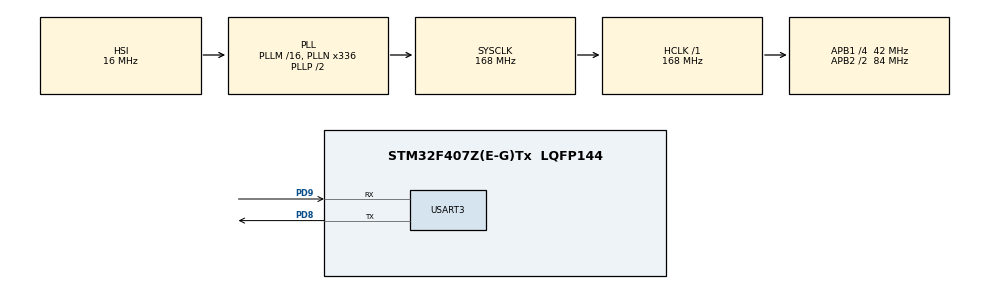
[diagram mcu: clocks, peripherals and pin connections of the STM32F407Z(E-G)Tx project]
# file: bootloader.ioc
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Dma.Request0=USART3_RX
Dma.Request1=USART3_TX
Dma.USART3_RX.0.Direction=DMA_PERIPH_TO_MEMORY
Dma.USART3_RX.0.FIFOMode=DMA_FIFOMODE_DISABLE
Dma.USART3_RX.0.Instance=DMA1_Stream1
Dma.USART3_RX.0.MemDataAlignment=DMA_MDATAALIGN_BYTE
Dma.USART3_RX.0.MemInc=DMA_MINC_ENABLE
Dma.USART3_RX.0.Mode=DMA_CIRCULAR
Dma.USART3_RX.0.PeriphDataAlignment=DMA_PDATAALIGN_BYTE
Dma.USART3_RX.0.PeriphInc=DMA_PINC_DISABLE
Dma.USART3_RX.0.Priority=DMA_PRIORITY_HIGH
Dma.USART3_TX.1.Direction=DMA_MEMORY_TO_PERIPH
Dma.USART3_TX.1.FIFOMode=DMA_FIFOMODE_DISABLE
Dma.USART3_TX.1.Instance=DMA1_Stream3
Dma.USART3_TX.1.MemDataAlignment=DMA_MDATAALIGN_BYTE
Dma.USART3_TX.1.MemInc=DMA_MINC_ENABLE
Dma.USART3_TX.1.Mode=DMA_CIRCULAR
Dma.USART3_TX.1.PeriphDataAlignment=DMA_PDATAALIGN_BYTE
Dma.USART3_TX.1.PeriphInc=DMA_PINC_DISABLE
Dma.USART3_TX.1.Priority=DMA_PRIORITY_HIGH
Mcu.Family=STM32F4
Mcu.Name=STM32F407Z(E-G)Tx
Mcu.Package=LQFP144
NVIC.DMA1_Stream1_IRQn=true\:2\:0\:true\:false\:true\:false\:true\:true
NVIC.DMA1_Stream3_IRQn=true\:2\:0\:true\:false\:true\:false\:true\:true
NVIC.PriorityGroup=NVIC_PRIORITYGROUP_4
NVIC.USART3_IRQn=true\:1\:0\:true\:false\:true\:false\:true\:true
PA13.Mode=Serial_Wire
PA13.Signal=SYS_JTMS-SWDIO
PA14.Mode=Serial_Wire
PA14.Signal=SYS_JTCK-SWCLK
PC14-OSC32_IN.Mode=LSE-External-Oscillator
PC14-OSC32_IN.Signal=RCC_OSC32_IN
PC15-OSC32_OUT.Mode=LSE-External-Oscillator
PC15-OSC32_OUT.Signal=RCC_OSC32_OUT
PD8.Mode=Asynchronous
PD8.Signal=USART3_TX
PD9.Mode=Asynchronous
PD9.Signal=USART3_RX
PH0-OSC_IN.Mode=HSE-External-Oscillator
PH0-OSC_IN.Signal=RCC_OSC_IN
PH1-OSC_OUT.Mode=HSE-External-Oscillator
PH1-OSC_OUT.Signal=RCC_OSC_OUT
ProjectManager.HeapSize=0x200
ProjectManager.StackSize=0x400
ProjectManager.TargetToolchain=MDK-ARM V5.32
RCC.48MHZClocksFreq_Value=84000000
RCC.AHBFreq_Value=168000000
RCC.APB1CLKDivider=RCC_HCLK_DIV4
RCC.APB1Freq_Value=42000000
RCC.APB1TimFreq_Value=84000000
RCC.APB2CLKDivider=RCC_HCLK_DIV2
RCC.APB2Freq_Value=84000000
RCC.APB2TimFreq_Value=168000000
RCC.CortexFreq_Value=168000000
RCC.HCLKFreq_Value=168000000
RCC.HSE_VALUE=25000000
RCC.HSI_VALUE=16000000
RCC.PLLN=336
RCC.SYSCLKFreq_VALUE=168000000
RCC.SYSCLKSource=RCC_SYSCLKSOURCE_PLLCLK
RCC.VCOOutputFreq_Value=336000000
USART3.VirtualMode=VM_ASYNC
board=custom

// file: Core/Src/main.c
/* USER CODE BEGIN Header */
/**
  ******************************************************************************
  * @file           : main.c
  * @brief          : Main program body
  ******************************************************************************
  * @attention
  *
  * Copyright (c) 2026 STMicroelectronics.
  * All rights reserved.
  *
  * This software is licensed under terms that can be found in the LICENSE file
  * in the root directory of this software component.
  * If no LICENSE file comes with this software, it is provided AS-IS.
  *
  ******************************************************************************
  */
/* USER CODE END Header */
#include "main.h"

/* USER CODE BEGIN Includes */
#include <stdio.h>
#include <stdint.h>
#include "ota_protocol.h"
#include "state_machine.h"
#include "ring_buffer.h"
#include "stm32f4xx_hal.h"
#include "task_monitor_boot.h"
/* USER CODE END Includes */

UART_HandleTypeDef huart3;
DMA_HandleTypeDef hdma_usart3_rx;
DMA_HandleTypeDef hdma_usart3_tx;

/* USER CODE BEGIN PV */
uint8_t rx_buffer[1200];
Ring_Buffer_ts uart_tp;
uint8_t parse_buffer[1200];
/* USER CODE END PV */

void SystemClock_Config(void);
static void MX_GPIO_Init(void);
static void MX_DMA_Init(void);
static void MX_USART3_UART_Init(void);
/* USER CODE BEGIN PFP */
int fputc(int ch,FILE *f)
{
  HAL_UART_Transmit(&huart3,(uint8_t*)&ch,1,10000);
  return ch;
}
/* USER CODE END PFP */

int main(void)
{

  /* MCU Configuration--------------------------------------------------------*/

  /* Reset of all peripherals, Initializes the Flash interface and the Systick. */
  HAL_Init();

  /* Configure the system clock */
  SystemClock_Config();

  /* Initialize all configured peripherals */
  MX_GPIO_Init();
  MX_DMA_Init();
  MX_USART3_UART_Init();
  /* USER CODE BEGIN 2 */
printf("\r\n====================================\r\n");
printf("Bootloader Started\r\n");
printf("\r\n====================================\r\n");

RingBuffer_Init(&uart_tp);

StateMachine_Init();

TaskMonitor_Init();

HAL_UARTEx_ReceiveToIdle_DMA(&huart3,rx_buffer,sizeof(rx_buffer));
__HAL_DMA_DISABLE_IT(&hdma_usart3_rx,DMA_IT_HT);

  /* USER CODE END 2 */

  /* Infinite loop */
  /* USER CODE BEGIN WHILE */
  while (1)
  {
    StateMachine_Run();
    TaskMonitor_Feed(TASK_ID_SM_RUN);

    for(;;)
    {
      uint32_t avail=RingBuffer_Available(&uart_tp);
      if(avail==0)
      {
        break;
      }

      uint32_t to_read=(avail>sizeof(parse_buffer))?sizeof(parse_buffer):avail;
      uint32_t read_len=RingBuffer_Read(&uart_tp,parse_buffer,to_read);

      ota_rx_flag=0;
      uint16_t used=OTA_Protocol_Parse(parse_buffer,(uint16_t)read_len);

      if(ota_rx_flag)
      {
        ota_rx_flag=0;
        StateMachine_OneFrameReceived();
      }

      if(used<read_len)
      {
        uart_tp.rd-=(read_len-used);
        if(used==0)
        {
          break;
        }
      }
    }
    TaskMonitor_Feed(TASK_ID_RINGBUF);
    TaskMonitor_Feed(TASK_ID_PROTOCOL_PARSE);
    TaskMonitor_Feed(TASK_ID_SM_RECEIVE);
    /* USER CODE END WHILE */

  }
}

void SystemClock_Config(void)
{
  RCC_OscInitTypeDef RCC_OscInitStruct = {0};
  RCC_ClkInitTypeDef RCC_ClkInitStruct = {0};

  /** Configure the main internal regulator output voltage
  */
  __HAL_RCC_PWR_CLK_ENABLE();
  __HAL_PWR_VOLTAGESCALING_CONFIG(PWR_REGULATOR_VOLTAGE_SCALE1);

  /** Initializes the RCC Oscillators according to the specified parameters
  * in the RCC_OscInitTypeDef structure.
  */
  RCC_OscInitStruct.OscillatorType = RCC_OSCILLATORTYPE_HSI;
  RCC_OscInitStruct.HSIState = RCC_HSI_ON;
  RCC_OscInitStruct.HSICalibrationValue = RCC_HSICALIBRATION_DEFAULT;
  RCC_OscInitStruct.PLL.PLLState = RCC_PLL_ON;
  RCC_OscInitStruct.PLL.PLLSource = RCC_PLLSOURCE_HSI;
  RCC_OscInitStruct.PLL.PLLM = 16;
  RCC_OscInitStruct.PLL.PLLN = 336;
  RCC_OscInitStruct.PLL.PLLP = RCC_PLLP_DIV2;
  RCC_OscInitStruct.PLL.PLLQ = 4;
  if (HAL_RCC_OscConfig(&RCC_OscInitStruct) != HAL_OK)
  {
    Error_Handler();
  }

  /** Initializes the CPU, AHB and APB buses clocks
  */
  RCC_ClkInitStruct.ClockType = RCC_CLOCKTYPE_HCLK|RCC_CLOCKTYPE_SYSCLK
                              |RCC_CLOCKTYPE_PCLK1|RCC_CLOCKTYPE_PCLK2;
  RCC_ClkInitStruct.SYSCLKSource = RCC_SYSCLKSOURCE_PLLCLK;
  RCC_ClkInitStruct.AHBCLKDivider = RCC_SYSCLK_DIV1;
  RCC_ClkInitStruct.APB1CLKDivider = RCC_HCLK_DIV4;
  RCC_ClkInitStruct.APB2CLKDivider = RCC_HCLK_DIV2;

  if (HAL_RCC_ClockConfig(&RCC_ClkInitStruct, FLASH_LATENCY_5) != HAL_OK)
  {
    Error_Handler();
  }
}

static void MX_USART3_UART_Init(void)
{

  huart3.Instance = USART3;
  huart3.Init.BaudRate = 115200;
  huart3.Init.WordLength = UART_WORDLENGTH_8B;
  huart3.Init.StopBits = UART_STOPBITS_1;
  huart3.Init.Parity = UART_PARITY_NONE;
  huart3.Init.Mode = UART_MODE_TX_RX;
  huart3.Init.HwFlowCtl = UART_HWCONTROL_NONE;
  huart3.Init.OverSampling = UART_OVERSAMPLING_16;
  if (HAL_UART_Init(&huart3) != HAL_OK)
  {
    Error_Handler();
  }

}

static void MX_DMA_Init(void)
{

  /* DMA controller clock enable */
  __HAL_RCC_DMA1_CLK_ENABLE();

  /* DMA interrupt init */
  /* DMA1_Stream1_IRQn interrupt configuration */
  HAL_NVIC_SetPriority(DMA1_Stream1_IRQn, 2, 0);
  HAL_NVIC_EnableIRQ(DMA1_Stream1_IRQn);
  /* DMA1_Stream3_IRQn interrupt configuration */
  HAL_NVIC_SetPriority(DMA1_Stream3_IRQn, 2, 0);
  HAL_NVIC_EnableIRQ(DMA1_Stream3_IRQn);

}

static void MX_GPIO_Init(void)
{

  /* GPIO Ports Clock Enable */
  __HAL_RCC_GPIOC_CLK_ENABLE();
  __HAL_RCC_GPIOH_CLK_ENABLE();
  __HAL_RCC_GPIOD_CLK_ENABLE();
  __HAL_RCC_GPIOA_CLK_ENABLE();

}

/* USER CODE BEGIN 4 */
void HAL_UARTEx_RxEventCallback(UART_HandleTypeDef *huart,uint16_t size)
{
  if(huart->Instance==USART3)
  {
    if(size>0)
    {
      if(!RingBuffer_Write(&uart_tp,rx_buffer,size))
      {
        printf("Write to Buffer Error\r\n");
      }
    }
    HAL_UARTEx_ReceiveToIdle_DMA(&huart3,rx_buffer,sizeof(rx_buffer));
    __HAL_DMA_DISABLE_IT(&hdma_usart3_rx,DMA_IT_HT);
  }
}

void HAL_UART_ErrorCallback(UART_HandleTypeDef *huart)
{
  if(huart->Instance==USART3)
  {
    huart->RxState=HAL_UART_STATE_READY;
    HAL_UARTEx_ReceiveToIdle_DMA(&huart3,rx_buffer,sizeof(rx_buffer));
    __HAL_DMA_DISABLE_IT(&hdma_usart3_rx,DMA_IT_HT);
  }
}

/* USER CODE END 4 */
#ifdef HH
void Error_Handler(void)
{
  __disable_irq();
  while (1)
  {
  }
}
#endif
